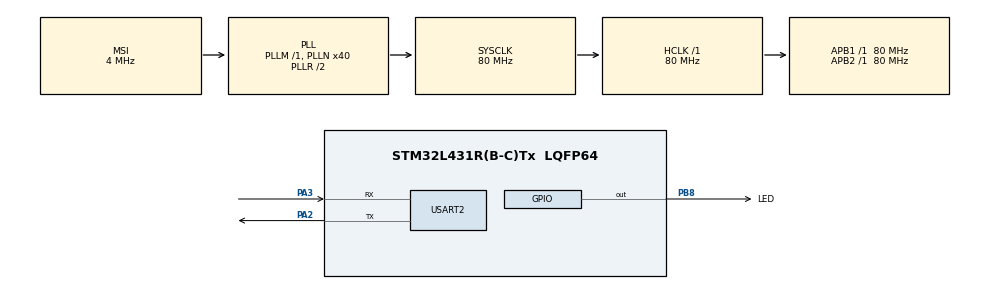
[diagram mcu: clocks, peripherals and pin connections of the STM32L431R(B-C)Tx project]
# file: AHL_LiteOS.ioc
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Mcu.Family=STM32L4
Mcu.Name=STM32L431R(B-C)Tx
Mcu.Package=LQFP64
NVIC.PriorityGroup=NVIC_PRIORITYGROUP_4
PA2.Mode=Asynchronous
PA2.Signal=USART2_TX
PA3.Mode=Asynchronous
PA3.Signal=USART2_RX
PB8.GPIO_Label=LED
PB8.Signal=GPIO_Output
ProjectManager.HeapSize=0x200
ProjectManager.StackSize=0x400
ProjectManager.TargetToolchain=MDK-ARM V5.32
RCC.AHBFreq_Value=80000000
RCC.APB1Freq_Value=80000000
RCC.APB1TimFreq_Value=80000000
RCC.APB2Freq_Value=80000000
RCC.APB2TimFreq_Value=80000000
RCC.CortexFreq_Value=80000000
RCC.HCLKFreq_Value=80000000
RCC.HSE_VALUE=8000000
RCC.HSI48_VALUE=48000000
RCC.HSI_VALUE=16000000
RCC.LSE_VALUE=32768
RCC.MSI_VALUE=4000000
RCC.PLLN=40
RCC.SYSCLKFreq_VALUE=80000000
RCC.SYSCLKSource=RCC_SYSCLKSOURCE_PLLCLK
RCC.VCOOutputFreq_Value=160000000
USART2.VirtualMode-Asynchronous=VM_ASYNC
board=custom

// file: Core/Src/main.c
/* USER CODE BEGIN Header */
/**
  ******************************************************************************
  * @file           : main.c
  * @brief          : Main program body
  ******************************************************************************
  * @attention
  *
  * Copyright (c) 2022 STMicroelectronics.
  * All rights reserved.
  *
  * This software is licensed under terms that can be found in the LICENSE file
  * in the root directory of this software component.
  * If no LICENSE file comes with this software, it is provided AS-IS.
  *
  ******************************************************************************
  */
/* USER CODE END Header */
#include "main.h"
#include "usart.h"
#include "gpio.h"
#include "stdio.h"
/* USER CODE BEGIN Includes */
#include "los_base.h"
#include "los_sys.h"
#include "los_typedef.h"
#include "los_task.h"
/* USER CODE END Includes */

void SystemClock_Config(void);

/* USER CODE BEGIN 0 */
void task(void)
{
	printf("LiteOS Task Start! \n");

	while(1)
	{
		printf("Green Light On\n");
		HAL_GPIO_WritePin(LED_GPIO_Port,LED_Pin,GPIO_PIN_RESET);
		LOS_TaskDelay(1000);

		printf("Green Light Off\n");
		HAL_GPIO_WritePin(LED_GPIO_Port,LED_Pin,GPIO_PIN_SET);
		LOS_TaskDelay(1000);
	}
}

UINT32 creat_task()
{
	UINT32 uwRet = LOS_OK;
	UINT32 g_TskHandle;
	TSK_INIT_PARAM_S task_init_param;
	task_init_param.usTaskPrio=0;
	task_init_param.pcName="task";
	task_init_param.pfnTaskEntry=(TSK_ENTRY_FUNC)task;
	task_init_param.uwStackSize=0x200;

	uwRet = LOS_TaskCreate(&g_TskHandle,&task_init_param);
	if(LOS_OK != uwRet)
	{
		return uwRet;

	}
	return uwRet;
}
/* USER CODE END 0 */

int main(void)
{

  /* MCU Configuration--------------------------------------------------------*/

  /* Reset of all peripherals, Initializes the Flash interface and the Systick. */
  HAL_Init();

  /* Configure the system clock */
  SystemClock_Config();

  /* Initialize all configured peripherals */
  MX_GPIO_Init();
  MX_USART2_UART_Init();
  /* USER CODE BEGIN 2 */
  UINT32 uwRet = LOS_KernelInit();
	if(uwRet != LOS_OK)
		return LOS_NOK;

	uwRet = creat_task();
	if(uwRet != LOS_OK)
		return LOS_NOK;

	LOS_Start();
  /* USER CODE END 2 */

  /* Infinite loop */
  while (1)
  {

  }
}

void SystemClock_Config(void)
{
  RCC_OscInitTypeDef RCC_OscInitStruct = {0};
  RCC_ClkInitTypeDef RCC_ClkInitStruct = {0};

  /** Configure the main internal regulator output voltage
  */
  if (HAL_PWREx_ControlVoltageScaling(PWR_REGULATOR_VOLTAGE_SCALE1) != HAL_OK)
  {
    Error_Handler();
  }

  /** Initializes the RCC Oscillators according to the specified parameters
  * in the RCC_OscInitTypeDef structure.
  */
  RCC_OscInitStruct.OscillatorType = RCC_OSCILLATORTYPE_MSI;
  RCC_OscInitStruct.MSIState = RCC_MSI_ON;
  RCC_OscInitStruct.MSICalibrationValue = 0;
  RCC_OscInitStruct.MSIClockRange = RCC_MSIRANGE_6;
  RCC_OscInitStruct.PLL.PLLState = RCC_PLL_ON;
  RCC_OscInitStruct.PLL.PLLSource = RCC_PLLSOURCE_MSI;
  RCC_OscInitStruct.PLL.PLLM = 1;
  RCC_OscInitStruct.PLL.PLLN = 40;
  RCC_OscInitStruct.PLL.PLLP = RCC_PLLP_DIV7;
  RCC_OscInitStruct.PLL.PLLQ = RCC_PLLQ_DIV2;
  RCC_OscInitStruct.PLL.PLLR = RCC_PLLR_DIV2;
  if (HAL_RCC_OscConfig(&RCC_OscInitStruct) != HAL_OK)
  {
    Error_Handler();
  }

  /** Initializes the CPU, AHB and APB buses clocks
  */
  RCC_ClkInitStruct.ClockType = RCC_CLOCKTYPE_HCLK|RCC_CLOCKTYPE_SYSCLK
                              |RCC_CLOCKTYPE_PCLK1|RCC_CLOCKTYPE_PCLK2;
  RCC_ClkInitStruct.SYSCLKSource = RCC_SYSCLKSOURCE_PLLCLK;
  RCC_ClkInitStruct.AHBCLKDivider = RCC_SYSCLK_DIV1;
  RCC_ClkInitStruct.APB1CLKDivider = RCC_HCLK_DIV1;
  RCC_ClkInitStruct.APB2CLKDivider = RCC_HCLK_DIV1;

  if (HAL_RCC_ClockConfig(&RCC_ClkInitStruct, FLASH_LATENCY_4) != HAL_OK)
  {
    Error_Handler();
  }
}

void Error_Handler(void)
{
  __disable_irq();
  while (1)
  {
  }
}
